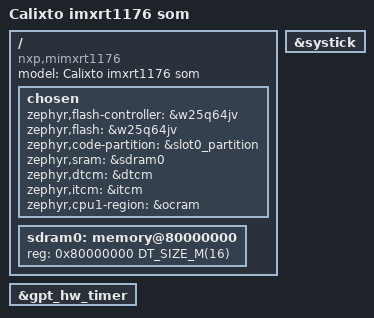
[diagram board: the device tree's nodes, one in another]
/*
 * Copyright 2026, Calixto Systems Pvt Ltd.
 *
 * SPDX-License-Identifier: Apache-2.0
 */

/dts-v1/;

#include <nxp/nxp_rt11xx_cm7.dtsi>
#include "imxrt1176_som.dtsi"

/ {
	model = "Calixto imxrt1176 som";
	compatible = "nxp,mimxrt1176";

	chosen {
		zephyr,flash-controller = &w25q64jv;
		zephyr,flash = &w25q64jv;
		zephyr,code-partition = &slot0_partition;
		zephyr,sram = &sdram0;
		zephyr,dtcm = &dtcm;
		zephyr,itcm = &itcm;
	    zephyr,cpu1-region = &ocram;
	};

	sdram0: memory@80000000 {
		device_type = "memory";
		reg = <0x80000000 DT_SIZE_M(16)>;
	};
};

&gpt_hw_timer {
	status = "okay";
};

&systick {
	status = "okay";
};
